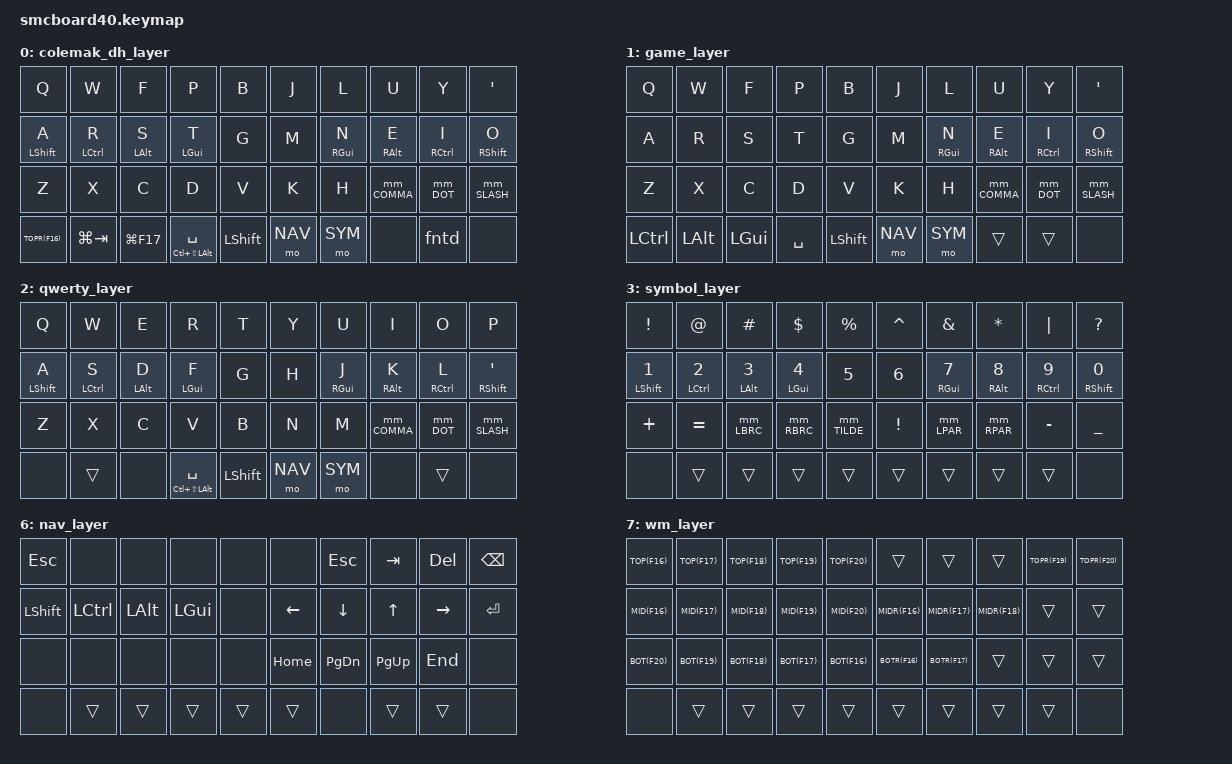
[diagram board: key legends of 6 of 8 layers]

/*
 * Copyright (c) 2021 The ZMK Contributors
 *
 * SPDX-License-Identifier: MIT
 */

#include <behaviors.dtsi>
#include <dt-bindings/zmk/keys.h>
#include "smcboard40-keypos.h"
#include "zmk_utils.h"

#define ALL 0xff
#define STD 0 2 3 4 5 6
#define BASEQ 0 2
#define BASE 0
#define GAME 1
#define QWRT 2
#define SYM  3
#define FN   4
#define FNOS 5
#define NAV  6
#define WM   7

#define KEYS_L LT0 LT1 LT2 LT3 LT4 LM0 LM1 LM2 LM3 LM4 LB0 LB1 LB2 LB3 LB4
#define KEYS_R RT0 RT1 RT2 RT3 RT4 RM0 RM1 RM2 RM3 RM4 RB0 RB1 RB2 RB3 RB4
#define THUMBS LH4 LH3 LH2 LH1 LH0 RH0 RH1 RH2 RH3 RH4

// ── Positional WM chord namespace ──────────────────────────────────────────
// F13-F20 are unmapped by macOS/apps, so any modifier combo on them is collision-free.
// WM is one layer, held via the LH0+RH0 combo. The chord reads as (row, hand, column):
//   ROW    : ctrl = top · alt = home · ctrl+alt = bottom
//   HAND   : shift = right hand
//   COLUMN : the F-key F16-F20
// F13/F14 (emitted by combos) = space prev/next. cmd is unused; nothing exceeds 3 modifiers.
#define TOP(k)    LC(k)            // top    row, left  / unshifted
#define TOPR(k)   LS(LC(k))        // top    row, right / shifted
#define MID(k)    LA(k)            // home/mid row, left  / unshifted  (MID not HOME: HOME is a keycode)
#define MIDR(k)   LS(LA(k))        // home/mid row, right / shifted
#define BOT(k)    LC(LA(k))        // bottom row, left  / unshifted
#define BOTR(k)   LS(LC(LA(k)))    // bottom row, right / shifted

#define COMBO_QT require-prior-idle-ms = <150>;
#define COMBO_FAST 35
#define COMBO_SLOW 35

/*                              40 KEY MATRIX / LAYOUT MAPPING

  ╭────────────────────────────────────────╮ ╭─────────────────────────────────────────╮
  │  0   1   2   3   4   5   6   7   8   9 │ │ LT4 LT3 LT2 LT1 LT0 RT0 RT1 RT2 RT3 RT4 │
  │ 10  11  12  13  14  15  16  17  18  19 │ │ LM4 LM3 LM2 LM1 LM0 RM0 RM1 RM2 RM3 RM4 │
  │ 20  21  22  23  24  25  26  27  28  29 │ │ LB4 LB3 LB2 LB1 LB0 RB0 RB1 RB2 RB3 RB4 │
  │ 30  31  32  33  34  35  36  37  38  39 │ │ LH4 LH3 LH2 LH1 LH0 RH0 RH1 RH2 RH3 RH4 │
  ╰────────────────────────────────────────╯ ╰─────────────────────────────────────────╯             */

&mt {
  //flavor = "tap-preferred";
  tapping_term_ms = <200>;
};

/ {
  behaviors {
    hml: hml {
      compatible = "zmk,behavior-hold-tap";
      #binding-cells = <2>;
      tapping-term-ms = <280>;
      quick-tap-ms = <175>;
      require-prior-idle-ms = <150>;
      flavor = "balanced";
      bindings = <&kp>, <&kp>;
      hold-trigger-key-positions = <KEYS_R THUMBS>;
      hold-trigger-on-release;
    };
    hmr: hmr {
      compatible = "zmk,behavior-hold-tap";
      #binding-cells = <2>;
      tapping-term-ms = <280>;
      quick-tap-ms = <175>;
      require-prior-idle-ms = <150>;
      flavor = "balanced";
      bindings = <&kp>, <&kp>;
      hold-trigger-key-positions = <KEYS_L THUMBS>;
      hold-trigger-on-release;
    };
    meh_spc: meh_spc {
      compatible = "zmk,behavior-hold-tap";
      #binding-cells = <2>;
      tapping-term-ms = <280>;
      quick-tap-ms = <175>;
      require-prior-idle-ms = <150>;
      flavor = "balanced";
      bindings = <&kp>, <&kp>;
    };
    skq: sticky_key_quick_release {
      compatible = "zmk,behavior-sticky-key";
      #binding-cells = <1>;
      bindings = <&kp>;
      release-after-ms = <1000>;
      quick-release;
      ignore-modifiers;
    };
    fntd: fntd {
      compatible = "zmk,behavior-tap-dance";
      #binding-cells = <0>;
      tapping-term-ms = <200>;
      bindings = <&mo FN>, <&mo FNOS>;
    };
    // tap: comma | shift + tap: semicolon
    MOD_MORPH(COMMA, (<&kp COMMA>, <&kp SEMI>), (<(MOD_LSFT|MOD_RSFT)>))

    // tap: dot | shift + tap: colon
    MOD_MORPH(DOT, (<&kp DOT>, <&kp COLON>), (<(MOD_LSFT|MOD_RSFT)>))

    // tap: ( | shift + tap: <
    MOD_MORPH(LPAR, (<&kp LPAR>, <&kp LT>), (<(MOD_LSFT|MOD_RSFT)>))
    // tap: ) | shift + tap: >
    MOD_MORPH(RPAR, (<&kp RPAR>, <&kp GT>), (<(MOD_LSFT|MOD_RSFT)>))

    // tap: { | shift + tap: [
    MOD_MORPH(LBRC, (<&kp LBRC>, <&kp LBKT>), (<(MOD_LSFT|MOD_RSFT)>))
    // tap: } | shift + tap: ]
    MOD_MORPH(RBRC, (<&kp RBRC>, <&kp RBKT>), (<(MOD_LSFT|MOD_RSFT)>))

    // tap: ~ | shift + tap: `
    MOD_MORPH(TILDE, (<&kp TILDE>, <&kp GRAVE>), (<(MOD_LSFT|MOD_RSFT)>))

    // tap: / | shift + tap: backslash
    MOD_MORPH(SLASH, (<&kp FSLH>, <&kp BSLH>), (<(MOD_LSFT|MOD_RSFT)>))

  };

  combos {
    compatible = "zmk,combos";
    // L hand tab combo (sends opt + ctl on hold)
    COMBO(TAB, &hml LA(LCTRL) TAB, LM2 LM3, STD, COMBO_FAST)
    COMBO(TAB_G, &kp TAB, LB4 LB3, GAME, COMBO_FAST)

    // ESC combo (sends opt + cmd on hold)
    COMBO(L_ESC, &hml LA(LGUI) ESC, LM1 LM2, STD, COMBO_FAST)
    COMBO(R_ESC, &hmr RA(RGUI) ESC, RM1 RM2, ALL, COMBO_FAST)
    COMBO(L_ESC_GAME, &kp ESC, LB2 LB1, GAME, COMBO_FAST)

    // Enter combos
    COMBO(L_ENTER, &kp ENTER, LB1 LB2, STD, COMBO_FAST)
    COMBO(R_ENTER, &hmr RA(RCTRL) ENTER, RM2 RM3, ALL, COMBO_FAST)

    // RST & BOOT
    COMBO(C_RST, &sys_reset, LT2 LT3, FN, COMBO_FAST)
    COMBO(C_BOOT, &bootloader, LT4 LT3, FN, COMBO_FAST)

    // WM activation — both inner thumbs hold the WM layer (BASE/QWRT only)
    COMBO(WM_ACT, &mo WM, LH0 RH0, BASEQ, 50)
    // global space prev/next — emit obscure F13/F14 chords for skhd (wrap handled in skhd)
    COMBO(SP_PREV, &kp LA(F13), LT3 LT2, BASEQ, COMBO_FAST)
    COMBO(SP_NEXT, &kp LA(F14), LT2 LT1, BASEQ, COMBO_FAST)

  };

  keymap {
    compatible = "zmk,keymap";

    colemak_dh_layer {
      bindings = <
        &kp Q &kp W &kp F &kp P &kp B &kp J &kp L &kp U &kp Y &kp SQT
        &hml LSHIFT A &hml LCTRL R &hml LALT S &hml LGUI T &kp G &kp M &hmr RGUI N &hmr RALT E &hmr RCTRL I &hmr RSHIFT O
        &kp Z &kp X &kp C &kp D &kp V &kp K &kp H &mm_COMMA &mm_DOT &mm_SLASH
        &kp TOPR(F16) &kp LG(TAB) &kp LG(F17) &meh_spc LC(LS(LALT)) SPC &kp LSHIFT &mo NAV &mo SYM &none &fntd &none
      >;
    };

    game_layer {
      bindings = <
        &kp Q &kp W &kp F &kp P &kp B &kp J &kp L &kp U &kp Y &kp SQT
        &kp A &kp R &kp S &kp T &kp G &kp M &hmr RGUI N &hmr RALT E &hmr RCTRL I &hmr RSHIFT O
        &kp Z &kp X &kp C &kp D &kp V &kp K &kp H &mm_COMMA &mm_DOT &mm_SLASH
        &kp LCTRL &kp LALT &kp LGUI &kp SPC &kp LSHIFT &mo NAV &mo SYM &trans &trans &none
      >;
    };

    qwerty_layer {
      bindings = <
        &kp Q &kp W &kp E &kp R &kp T &kp Y &kp U &kp I &kp O &kp P
        &hml LSHIFT A &hml LCTRL S &hml LALT D &hml LGUI F &kp G &kp H &hmr RGUI J &hmr RALT K &hmr RCTRL L &hmr RSHIFT SQT
        &kp Z &kp X &kp C &kp V &kp B &kp N &kp M &mm_COMMA &mm_DOT &mm_SLASH
        &none &trans &none &meh_spc LC(LS(LALT)) SPC &kp LSHIFT &mo NAV &mo SYM &none &trans &none
      >;
    };

    symbol_layer {
      bindings = <
       &kp EXCL &kp AT &kp HASH &kp DOLLAR &kp PERCENT &kp CARET &kp AMPERSAND &kp ASTERISK &kp PIPE &kp QMARK
       &hml LSHFT N1 &hml LCTRL N2 &hml LALT N3 &hml LGUI N4 &kp N5 &kp N6 &hmr RGUI N7 &hmr RALT N8 &hmr RCTRL N9 &hmr RSHFT N0
       &kp PLUS &kp EQUAL &mm_LBRC &mm_RBRC &mm_TILDE &kp EXCL &mm_LPAR &mm_RPAR &kp MINUS &kp UNDER
       &none &trans &trans &trans &trans &trans &trans &trans &trans &none
      >;
    };

    function_layer {
      bindings = <
        &kp F11 &kp F12 &none &none &none &none &none &to BASE &to QWRT &to GAME
        &kp F1 &kp F2 &kp F3 &kp F4 &kp F5 &kp F6 &kp F7 &kp F8 &kp F9 &kp F10
        &kp C_BRI_DN &kp C_BRI_UP &kp C_VOL_DN &kp C_VOL_UP &none &none &none
        &none &trans &trans &trans &trans &trans &trans &trans &trans &none
      >;
    };

    function_osm_layer {
      bindings = <
        &skq F11 &skq F12 &none &none &none &none &none &none &none &none
        &skq F1 &skq F2 &skq F3 &skq F4 &skq F5 &skq F6 &skq F7 &skq F8 &skq F9 &skq F10
        &none &none &none &none &none &none &none
        &none &trans &trans &trans &trans &trans &trans &trans &trans &none
      >;
    };

    nav_layer {
      bindings = <
       &kp ESC &none &none &none &none &none &kp ESC &kp TAB &kp DEL &kp BSPC
       &kp LSHFT &kp LCTRL &kp LALT &kp LGUI &none &kp LEFT &kp DOWN &kp UP &kp RIGHT &kp ENTER
       &none &none &none &none &none &kp HOME &kp PG_DN &kp PG_UP &kp END &none
       &none &trans &trans &trans &trans &trans &none &trans &trans &none
      >;
    };

    // WM — window management (HOLD LH0+RH0 combo), single layer. F16-F20 = column.
    //   L top  ctrl        send-window-to-space 1-5
    //   L home alt         go-to-space 1-5
    //   L bot  ctrl+alt    balance · swap-prev · swap-next · focus-prev · focus-next
    //   R top  ctrl+shift  split bsp/stack  (float/fullscreen/zoom-parent moved to BASE thumbs)
    //   R home alt+shift   mirror-x mirror-y rotate-90
    //   R bot  ctrl+alt+sh restart-yabai restart-skhd
    wm_layer {
      bindings = <
        &kp TOP(F16) &kp TOP(F17) &kp TOP(F18) &kp TOP(F19) &kp TOP(F20) &trans &trans &trans &kp TOPR(F19) &kp TOPR(F20)
        &kp MID(F16) &kp MID(F17) &kp MID(F18) &kp MID(F19) &kp MID(F20) &kp MIDR(F16) &kp MIDR(F17) &kp MIDR(F18) &trans &trans
        &kp BOT(F20) &kp BOT(F19) &kp BOT(F18) &kp BOT(F17) &kp BOT(F16) &kp BOTR(F16) &kp BOTR(F17) &trans &trans &trans
        &none &trans &trans &trans &trans &trans &trans &trans &trans &none
      >;
    };

  };
};

